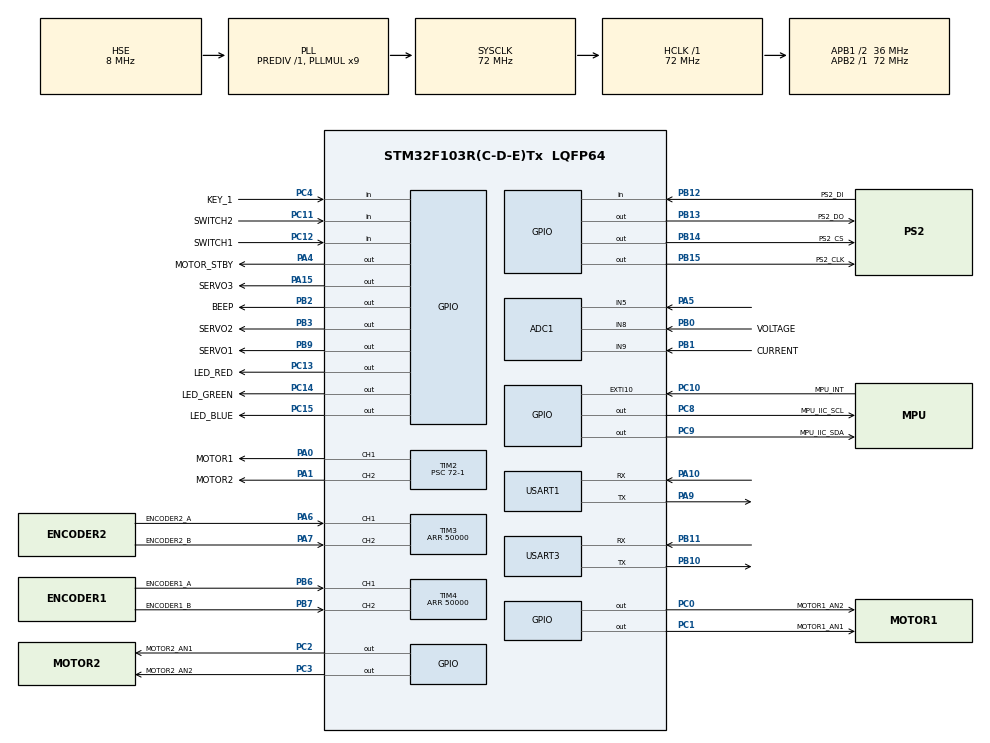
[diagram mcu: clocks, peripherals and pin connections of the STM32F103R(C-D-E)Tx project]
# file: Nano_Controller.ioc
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ADC1.Channel-0\#ChannelRegularConversion=ADC_CHANNEL_8
ADC1.NbrOfConversionFlag=1
ADC1.Rank-0\#ChannelRegularConversion=1
ADC1.SamplingTime-0\#ChannelRegularConversion=ADC_SAMPLETIME_1CYCLE_5
ADC1.master=1
Dma.Request0=USART1_RX
Dma.Request1=USART1_TX
Dma.USART1_RX.0.Direction=DMA_PERIPH_TO_MEMORY
Dma.USART1_RX.0.Instance=DMA1_Channel5
Dma.USART1_RX.0.MemDataAlignment=DMA_MDATAALIGN_BYTE
Dma.USART1_RX.0.MemInc=DMA_MINC_ENABLE
Dma.USART1_RX.0.Mode=DMA_NORMAL
Dma.USART1_RX.0.PeriphDataAlignment=DMA_PDATAALIGN_BYTE
Dma.USART1_RX.0.PeriphInc=DMA_PINC_DISABLE
Dma.USART1_RX.0.Priority=DMA_PRIORITY_LOW
Dma.USART1_TX.1.Direction=DMA_MEMORY_TO_PERIPH
Dma.USART1_TX.1.Instance=DMA1_Channel4
Dma.USART1_TX.1.MemDataAlignment=DMA_MDATAALIGN_BYTE
Dma.USART1_TX.1.MemInc=DMA_MINC_ENABLE
Dma.USART1_TX.1.Mode=DMA_NORMAL
Dma.USART1_TX.1.PeriphDataAlignment=DMA_PDATAALIGN_BYTE
Dma.USART1_TX.1.PeriphInc=DMA_PINC_DISABLE
Dma.USART1_TX.1.Priority=DMA_PRIORITY_LOW
Mcu.Family=STM32F1
Mcu.Name=STM32F103R(C-D-E)Tx
Mcu.Package=LQFP64
NVIC.DMA1_Channel4_IRQn=true\:0\:0\:false\:true\:true\:1\:false\:true
NVIC.DMA1_Channel5_IRQn=true\:0\:0\:false\:true\:true\:2\:false\:true
NVIC.EXTI15_10_IRQn=true\:0\:0\:true\:false\:true\:true\:true
NVIC.PriorityGroup=NVIC_PRIORITYGROUP_4
NVIC.TIM1_UP_IRQn=true\:0\:0\:false\:false\:true\:true\:true
NVIC.TIM3_IRQn=true\:0\:0\:false\:false\:true\:true\:true
NVIC.TIM4_IRQn=true\:0\:0\:false\:false\:true\:true\:true
NVIC.USART1_IRQn=true\:0\:0\:false\:false\:true\:true\:true
PA0-WKUP.GPIO_Label=MOTOR1
PA0-WKUP.Signal=S_TIM2_CH1_ETR
PA1.GPIO_Label=MOTOR2
PA1.Signal=S_TIM2_CH2
PA10.Mode=Asynchronous
PA10.Signal=USART1_RX
PA13.Mode=Serial_Wire
PA13.Signal=SYS_JTMS-SWDIO
PA14.Mode=Serial_Wire
PA14.Signal=SYS_JTCK-SWCLK
PA15.GPIO_Label=SERVO3
PA15.Signal=GPIO_Output
PA4.GPIO_Label=MOTOR_STBY
PA4.Signal=GPIO_Output
PA5.Signal=ADCx_IN5
PA6.GPIO_Label=ENCODER2_A
PA6.GPIO_PuPd=GPIO_PULLUP
PA6.Signal=S_TIM3_CH1
PA7.GPIO_Label=ENCODER2_B
PA7.GPIO_PuPd=GPIO_PULLUP
PA7.Signal=S_TIM3_CH2
PA9.Mode=Asynchronous
PA9.Signal=USART1_TX
PB0.GPIO_Label=VOLTAGE
PB0.Signal=ADCx_IN8
PB1.GPIO_Label=CURRENT
PB1.Signal=ADCx_IN9
PB10.Mode=Asynchronous
PB10.Signal=USART3_TX
PB11.Mode=Asynchronous
PB11.Signal=USART3_RX
PB12.GPIO_Label=PS2_DI
PB12.GPIO_PuPd=GPIO_PULLUP
PB12.Signal=GPIO_Input
PB13.GPIO_Label=PS2_DO
PB13.GPIO_PuPd=GPIO_PULLUP
PB13.Signal=GPIO_Output
PB14.GPIO_Label=PS2_CS
PB14.GPIO_PuPd=GPIO_PULLUP
PB14.Signal=GPIO_Output
PB15.GPIO_Label=PS2_CLK
PB15.GPIO_PuPd=GPIO_PULLUP
PB15.Signal=GPIO_Output
PB2.GPIO_Label=BEEP
PB2.Signal=GPIO_Output
PB3.GPIO_Label=SERVO2
PB3.Signal=GPIO_Output
PB6.GPIO_Label=ENCODER1_A
PB6.GPIO_PuPd=GPIO_PULLUP
PB6.Signal=S_TIM4_CH1
PB7.GPIO_Label=ENCODER1_B
PB7.GPIO_PuPd=GPIO_PULLUP
PB7.Signal=S_TIM4_CH2
PB9.GPIO_Label=SERVO1
PB9.Signal=GPIO_Output
PC0.GPIO_Label=MOTOR1_AN2
PC0.Signal=GPIO_Output
PC1.GPIO_Label=MOTOR1_AN1
PC1.Signal=GPIO_Output
PC10.GPIO_Label=MPU_INT
PC10.Signal=GPXTI10
PC11.GPIO_Label=SWITCH2
PC11.GPIO_PuPd=GPIO_PULLUP
PC11.Signal=GPIO_Input
PC12.GPIO_Label=SWITCH1
PC12.GPIO_PuPd=GPIO_PULLUP
PC12.Signal=GPIO_Input
PC13-TAMPER-RTC.GPIO_Label=LED_RED
PC13-TAMPER-RTC.Signal=GPIO_Output
PC14-OSC32_IN.GPIO_Label=LED_GREEN
PC14-OSC32_IN.Signal=GPIO_Output
PC15-OSC32_OUT.GPIO_Label=LED_BLUE
PC15-OSC32_OUT.Signal=GPIO_Output
PC2.GPIO_Label=MOTOR2_AN1
PC2.Signal=GPIO_Output
PC3.GPIO_Label=MOTOR2_AN2
PC3.Signal=GPIO_Output
PC4.GPIO_Label=KEY_1
PC4.GPIO_PuPd=GPIO_PULLUP
PC4.Signal=GPIO_Input
PC8.GPIO_Label=MPU_IIC_SCL
PC8.Signal=GPIO_Output
PC9.GPIO_Label=MPU_IIC_SDA
PC9.Signal=GPIO_Output
PD0-OSC_IN.Mode=HSE-External-Oscillator
PD0-OSC_IN.Signal=RCC_OSC_IN
PD1-OSC_OUT.Mode=HSE-External-Oscillator
PD1-OSC_OUT.Signal=RCC_OSC_OUT
ProjectManager.HeapSize=0x200
ProjectManager.StackSize=0x400
ProjectManager.TargetToolchain=MDK-ARM V5
RCC.ADCPresc=RCC_ADCPCLK2_DIV6
RCC.AHBFreq_Value=72000000
RCC.APB1CLKDivider=RCC_HCLK_DIV2
RCC.APB1Freq_Value=36000000
RCC.APB1TimFreq_Value=72000000
RCC.APB2Freq_Value=72000000
RCC.APB2TimFreq_Value=72000000
RCC.HCLKFreq_Value=72000000
RCC.PLLMUL=RCC_PLL_MUL9
RCC.PLLSourceVirtual=RCC_PLLSOURCE_HSE
RCC.SYSCLKFreq_VALUE=72000000
RCC.SYSCLKSource=RCC_SYSCLKSOURCE_PLLCLK
RCC.USBFreq_Value=48000000
RCC.USBPrescaler=RCC_USBCLKSOURCE_PLL_DIV1_5
SH.ADCx_IN5.0=ADC1_IN5,IN5
SH.ADCx_IN8.0=ADC1_IN8,IN8
SH.ADCx_IN9.0=ADC1_IN9,IN9
SH.S_TIM2_CH1_ETR.0=TIM2_CH1,PWM Generation1 CH1
SH.S_TIM2_CH2.0=TIM2_CH2,PWM Generation2 CH2
SH.S_TIM3_CH1.0=TIM3_CH1,Encoder_Interface
SH.S_TIM3_CH2.0=TIM3_CH2,Encoder_Interface
SH.S_TIM4_CH1.0=TIM4_CH1,Encoder_Interface
SH.S_TIM4_CH2.0=TIM4_CH2,Encoder_Interface
TIM1.Period=1500-1
TIM1.Prescaler=72-1
TIM2.Channel-PWM\ Generation1\ CH1=TIM_CHANNEL_1
TIM2.Channel-PWM\ Generation2\ CH2=TIM_CHANNEL_2
TIM2.Period=1000-1
TIM2.Prescaler=72-1
TIM3.ClockDivision=TIM_CLOCKDIVISION_DIV4
TIM3.EncoderMode=TIM_ENCODERMODE_TI12
TIM3.IC1Filter=15
TIM3.IC2Filter=15
TIM3.Period=50000
TIM4.ClockDivision=TIM_CLOCKDIVISION_DIV4
TIM4.EncoderMode=TIM_ENCODERMODE_TI12
TIM4.IC1Filter=15
TIM4.IC2Filter=15
TIM4.Period=50000
USART1.VirtualMode=VM_ASYNC
USART3.VirtualMode=VM_ASYNC
VP_TIM1_VS_ClockSourceINT.Mode=Internal
board=custom

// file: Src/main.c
/* USER CODE BEGIN Header */
/**
  ******************************************************************************
  * @file           : main.c
  * @brief          : Main program body
  ******************************************************************************
  ** This notice applies to any and all portions of this file
  * that are not between comment pairs USER CODE BEGIN and
  * USER CODE END. Other portions of this file, whether
  * inserted by the user or by software development tools
  * are owned by their respective copyright owners.
  *
  * COPYRIGHT(c) 2019 STMicroelectronics
  *
  * Redistribution and use in source and binary forms, with or without modification,
  * are permitted provided that the following conditions are met:
  *   1. Redistributions of source code must retain the above copyright notice,
  *      this list of conditions and the following disclaimer.
  *   2. Redistributions in binary form must reproduce the above copyright notice,
  *      this list of conditions and the following disclaimer in the documentation
  *      and/or other materials provided with the distribution.
  *   3. Neither the name of STMicroelectronics nor the names of its contributors
  *      may be used to endorse or promote products derived from this software
  *      without specific prior written permission.
  *
  * THIS SOFTWARE IS PROVIDED BY THE COPYRIGHT HOLDERS AND CONTRIBUTORS "AS IS"
  * AND ANY EXPRESS OR IMPLIED WARRANTIES, INCLUDING, BUT NOT LIMITED TO, THE
  * IMPLIED WARRANTIES OF MERCHANTABILITY AND FITNESS FOR A PARTICULAR PURPOSE ARE
  * DISCLAIMED. IN NO EVENT SHALL THE COPYRIGHT HOLDER OR CONTRIBUTORS BE LIABLE
  * FOR ANY DIRECT, INDIRECT, INCIDENTAL, SPECIAL, EXEMPLARY, OR CONSEQUENTIAL
  * DAMAGES (INCLUDING, BUT NOT LIMITED TO, PROCUREMENT OF SUBSTITUTE GOODS OR
  * SERVICES; LOSS OF USE, DATA, OR PROFITS; OR BUSINESS INTERRUPTION) HOWEVER
  * CAUSED AND ON ANY THEORY OF LIABILITY, WHETHER IN CONTRACT, STRICT LIABILITY,
  * OR TORT (INCLUDING NEGLIGENCE OR OTHERWISE) ARISING IN ANY WAY OUT OF THE USE
  * OF THIS SOFTWARE, EVEN IF ADVISED OF THE POSSIBILITY OF SUCH DAMAGE.
  *
  ******************************************************************************
  */
/* USER CODE END Header */

#include "main.h"

/* USER CODE BEGIN Includes */
#include "mainloop.h"
/* USER CODE END Includes */

ADC_HandleTypeDef hadc1;

TIM_HandleTypeDef htim1;
TIM_HandleTypeDef htim2;
TIM_HandleTypeDef htim3;
TIM_HandleTypeDef htim4;

UART_HandleTypeDef huart1;
UART_HandleTypeDef huart3;
DMA_HandleTypeDef hdma_usart1_rx;
DMA_HandleTypeDef hdma_usart1_tx;

void SystemClock_Config(void);
static void MX_GPIO_Init(void);
static void MX_DMA_Init(void);
static void MX_TIM4_Init(void);
static void MX_ADC1_Init(void);
static void MX_TIM3_Init(void);
static void MX_USART1_UART_Init(void);
static void MX_TIM1_Init(void);
static void MX_TIM2_Init(void);
static void MX_USART3_UART_Init(void);
static void MX_NVIC_Init(void);

int main(void)
{

  /* MCU Configuration--------------------------------------------------------*/

  /* Reset of all peripherals, Initializes the Flash interface and the Systick. */
  HAL_Init();

  /* Configure the system clock */
  SystemClock_Config();

  /* Initialize all configured peripherals */
  MX_GPIO_Init();
  MX_DMA_Init();
  MX_TIM4_Init();
  MX_ADC1_Init();
  MX_TIM3_Init();
  MX_USART1_UART_Init();
  MX_TIM1_Init();
  MX_TIM2_Init();
  MX_USART3_UART_Init();

  /* Initialize interrupts */
  MX_NVIC_Init();

  /* Infinite loop */
  /* USER CODE BEGIN WHILE */

	/*main loop*/
  while (1){
		vMainLoop();
    /* USER CODE END WHILE */

  }
}

void SystemClock_Config(void)
{
  RCC_OscInitTypeDef RCC_OscInitStruct = {0};
  RCC_ClkInitTypeDef RCC_ClkInitStruct = {0};
  RCC_PeriphCLKInitTypeDef PeriphClkInit = {0};

  /** Initializes the CPU, AHB and APB busses clocks
  */
  RCC_OscInitStruct.OscillatorType = RCC_OSCILLATORTYPE_HSE;
  RCC_OscInitStruct.HSEState = RCC_HSE_ON;
  RCC_OscInitStruct.HSEPredivValue = RCC_HSE_PREDIV_DIV1;
  RCC_OscInitStruct.HSIState = RCC_HSI_ON;
  RCC_OscInitStruct.PLL.PLLState = RCC_PLL_ON;
  RCC_OscInitStruct.PLL.PLLSource = RCC_PLLSOURCE_HSE;
  RCC_OscInitStruct.PLL.PLLMUL = RCC_PLL_MUL9;
  if (HAL_RCC_OscConfig(&RCC_OscInitStruct) != HAL_OK)
  {
    Error_Handler();
  }
  /** Initializes the CPU, AHB and APB busses clocks
  */
  RCC_ClkInitStruct.ClockType = RCC_CLOCKTYPE_HCLK|RCC_CLOCKTYPE_SYSCLK
                              |RCC_CLOCKTYPE_PCLK1|RCC_CLOCKTYPE_PCLK2;
  RCC_ClkInitStruct.SYSCLKSource = RCC_SYSCLKSOURCE_PLLCLK;
  RCC_ClkInitStruct.AHBCLKDivider = RCC_SYSCLK_DIV1;
  RCC_ClkInitStruct.APB1CLKDivider = RCC_HCLK_DIV2;
  RCC_ClkInitStruct.APB2CLKDivider = RCC_HCLK_DIV1;

  if (HAL_RCC_ClockConfig(&RCC_ClkInitStruct, FLASH_LATENCY_2) != HAL_OK)
  {
    Error_Handler();
  }
  PeriphClkInit.PeriphClockSelection = RCC_PERIPHCLK_ADC;
  PeriphClkInit.AdcClockSelection = RCC_ADCPCLK2_DIV6;
  if (HAL_RCCEx_PeriphCLKConfig(&PeriphClkInit) != HAL_OK)
  {
    Error_Handler();
  }
}

/**
  * @brief NVIC Configuration.
  * @retval None
  */
static void MX_NVIC_Init(void)
{
  /* DMA1_Channel4_IRQn interrupt configuration */
  HAL_NVIC_SetPriority(DMA1_Channel4_IRQn, 0, 0);
  HAL_NVIC_EnableIRQ(DMA1_Channel4_IRQn);
  /* DMA1_Channel5_IRQn interrupt configuration */
  HAL_NVIC_SetPriority(DMA1_Channel5_IRQn, 0, 0);
  HAL_NVIC_EnableIRQ(DMA1_Channel5_IRQn);
}

static void MX_ADC1_Init(void)
{

  ADC_ChannelConfTypeDef sConfig = {0};

  /** Common config
  */
  hadc1.Instance = ADC1;
  hadc1.Init.ScanConvMode = ADC_SCAN_DISABLE;
  hadc1.Init.ContinuousConvMode = DISABLE;
  hadc1.Init.DiscontinuousConvMode = DISABLE;
  hadc1.Init.ExternalTrigConv = ADC_SOFTWARE_START;
  hadc1.Init.DataAlign = ADC_DATAALIGN_RIGHT;
  hadc1.Init.NbrOfConversion = 1;
  if (HAL_ADC_Init(&hadc1) != HAL_OK)
  {
    Error_Handler();
  }
  /** Configure Regular Channel
  */
  sConfig.Channel = ADC_CHANNEL_8;
  sConfig.Rank = ADC_REGULAR_RANK_1;
  sConfig.SamplingTime = ADC_SAMPLETIME_1CYCLE_5;
  if (HAL_ADC_ConfigChannel(&hadc1, &sConfig) != HAL_OK)
  {
    Error_Handler();
  }

}

static void MX_TIM1_Init(void)
{

  TIM_ClockConfigTypeDef sClockSourceConfig = {0};
  TIM_MasterConfigTypeDef sMasterConfig = {0};

  htim1.Instance = TIM1;
  htim1.Init.Prescaler = 72-1;
  htim1.Init.CounterMode = TIM_COUNTERMODE_UP;
  htim1.Init.Period = 1500-1;
  htim1.Init.ClockDivision = TIM_CLOCKDIVISION_DIV1;
  htim1.Init.RepetitionCounter = 0;
  htim1.Init.AutoReloadPreload = TIM_AUTORELOAD_PRELOAD_DISABLE;
  if (HAL_TIM_Base_Init(&htim1) != HAL_OK)
  {
    Error_Handler();
  }
  sClockSourceConfig.ClockSource = TIM_CLOCKSOURCE_INTERNAL;
  if (HAL_TIM_ConfigClockSource(&htim1, &sClockSourceConfig) != HAL_OK)
  {
    Error_Handler();
  }
  sMasterConfig.MasterOutputTrigger = TIM_TRGO_RESET;
  sMasterConfig.MasterSlaveMode = TIM_MASTERSLAVEMODE_DISABLE;
  if (HAL_TIMEx_MasterConfigSynchronization(&htim1, &sMasterConfig) != HAL_OK)
  {
    Error_Handler();
  }

}

static void MX_TIM2_Init(void)
{

  TIM_MasterConfigTypeDef sMasterConfig = {0};
  TIM_OC_InitTypeDef sConfigOC = {0};

  htim2.Instance = TIM2;
  htim2.Init.Prescaler = 72-1;
  htim2.Init.CounterMode = TIM_COUNTERMODE_UP;
  htim2.Init.Period = 1000-1;
  htim2.Init.ClockDivision = TIM_CLOCKDIVISION_DIV1;
  htim2.Init.AutoReloadPreload = TIM_AUTORELOAD_PRELOAD_DISABLE;
  if (HAL_TIM_PWM_Init(&htim2) != HAL_OK)
  {
    Error_Handler();
  }
  sMasterConfig.MasterOutputTrigger = TIM_TRGO_RESET;
  sMasterConfig.MasterSlaveMode = TIM_MASTERSLAVEMODE_DISABLE;
  if (HAL_TIMEx_MasterConfigSynchronization(&htim2, &sMasterConfig) != HAL_OK)
  {
    Error_Handler();
  }
  sConfigOC.OCMode = TIM_OCMODE_PWM1;
  sConfigOC.Pulse = 0;
  sConfigOC.OCPolarity = TIM_OCPOLARITY_HIGH;
  sConfigOC.OCFastMode = TIM_OCFAST_DISABLE;
  if (HAL_TIM_PWM_ConfigChannel(&htim2, &sConfigOC, TIM_CHANNEL_1) != HAL_OK)
  {
    Error_Handler();
  }
  if (HAL_TIM_PWM_ConfigChannel(&htim2, &sConfigOC, TIM_CHANNEL_2) != HAL_OK)
  {
    Error_Handler();
  }
  HAL_TIM_MspPostInit(&htim2);

}

static void MX_TIM3_Init(void)
{

  TIM_Encoder_InitTypeDef sConfig = {0};
  TIM_MasterConfigTypeDef sMasterConfig = {0};

  htim3.Instance = TIM3;
  htim3.Init.Prescaler = 0;
  htim3.Init.CounterMode = TIM_COUNTERMODE_UP;
  htim3.Init.Period = 50000;
  htim3.Init.ClockDivision = TIM_CLOCKDIVISION_DIV4;
  htim3.Init.AutoReloadPreload = TIM_AUTORELOAD_PRELOAD_DISABLE;
  sConfig.EncoderMode = TIM_ENCODERMODE_TI12;
  sConfig.IC1Polarity = TIM_ICPOLARITY_RISING;
  sConfig.IC1Selection = TIM_ICSELECTION_DIRECTTI;
  sConfig.IC1Prescaler = TIM_ICPSC_DIV1;
  sConfig.IC1Filter = 15;
  sConfig.IC2Polarity = TIM_ICPOLARITY_RISING;
  sConfig.IC2Selection = TIM_ICSELECTION_DIRECTTI;
  sConfig.IC2Prescaler = TIM_ICPSC_DIV1;
  sConfig.IC2Filter = 15;
  if (HAL_TIM_Encoder_Init(&htim3, &sConfig) != HAL_OK)
  {
    Error_Handler();
  }
  sMasterConfig.MasterOutputTrigger = TIM_TRGO_RESET;
  sMasterConfig.MasterSlaveMode = TIM_MASTERSLAVEMODE_DISABLE;
  if (HAL_TIMEx_MasterConfigSynchronization(&htim3, &sMasterConfig) != HAL_OK)
  {
    Error_Handler();
  }

}

static void MX_TIM4_Init(void)
{

  TIM_Encoder_InitTypeDef sConfig = {0};
  TIM_MasterConfigTypeDef sMasterConfig = {0};

  htim4.Instance = TIM4;
  htim4.Init.Prescaler = 0;
  htim4.Init.CounterMode = TIM_COUNTERMODE_UP;
  htim4.Init.Period = 50000;
  htim4.Init.ClockDivision = TIM_CLOCKDIVISION_DIV4;
  htim4.Init.AutoReloadPreload = TIM_AUTORELOAD_PRELOAD_DISABLE;
  sConfig.EncoderMode = TIM_ENCODERMODE_TI12;
  sConfig.IC1Polarity = TIM_ICPOLARITY_RISING;
  sConfig.IC1Selection = TIM_ICSELECTION_DIRECTTI;
  sConfig.IC1Prescaler = TIM_ICPSC_DIV1;
  sConfig.IC1Filter = 15;
  sConfig.IC2Polarity = TIM_ICPOLARITY_RISING;
  sConfig.IC2Selection = TIM_ICSELECTION_DIRECTTI;
  sConfig.IC2Prescaler = TIM_ICPSC_DIV1;
  sConfig.IC2Filter = 15;
  if (HAL_TIM_Encoder_Init(&htim4, &sConfig) != HAL_OK)
  {
    Error_Handler();
  }
  sMasterConfig.MasterOutputTrigger = TIM_TRGO_RESET;
  sMasterConfig.MasterSlaveMode = TIM_MASTERSLAVEMODE_DISABLE;
  if (HAL_TIMEx_MasterConfigSynchronization(&htim4, &sMasterConfig) != HAL_OK)
  {
    Error_Handler();
  }

}

static void MX_USART1_UART_Init(void)
{

  huart1.Instance = USART1;
  huart1.Init.BaudRate = 115200;
  huart1.Init.WordLength = UART_WORDLENGTH_8B;
  huart1.Init.StopBits = UART_STOPBITS_1;
  huart1.Init.Parity = UART_PARITY_NONE;
  huart1.Init.Mode = UART_MODE_TX_RX;
  huart1.Init.HwFlowCtl = UART_HWCONTROL_NONE;
  huart1.Init.OverSampling = UART_OVERSAMPLING_16;
  if (HAL_UART_Init(&huart1) != HAL_OK)
  {
    Error_Handler();
  }

}

static void MX_USART3_UART_Init(void)
{

  huart3.Instance = USART3;
  huart3.Init.BaudRate = 115200;
  huart3.Init.WordLength = UART_WORDLENGTH_8B;
  huart3.Init.StopBits = UART_STOPBITS_1;
  huart3.Init.Parity = UART_PARITY_NONE;
  huart3.Init.Mode = UART_MODE_TX_RX;
  huart3.Init.HwFlowCtl = UART_HWCONTROL_NONE;
  huart3.Init.OverSampling = UART_OVERSAMPLING_16;
  if (HAL_UART_Init(&huart3) != HAL_OK)
  {
    Error_Handler();
  }

}

static void MX_DMA_Init(void)
{
  /* DMA controller clock enable */
  __HAL_RCC_DMA1_CLK_ENABLE();

}

static void MX_GPIO_Init(void)
{
  GPIO_InitTypeDef GPIO_InitStruct = {0};

  /* GPIO Ports Clock Enable */
  __HAL_RCC_GPIOC_CLK_ENABLE();
  __HAL_RCC_GPIOD_CLK_ENABLE();
  __HAL_RCC_GPIOA_CLK_ENABLE();
  __HAL_RCC_GPIOB_CLK_ENABLE();

  /*Configure GPIO pin Output Level */
  HAL_GPIO_WritePin(GPIOC, LED_RED_Pin|LED_GREEN_Pin|LED_BLUE_Pin|MOTOR1_AN2_Pin
                          |MOTOR1_AN1_Pin|MOTOR2_AN1_Pin|MOTOR2_AN2_Pin|MPU_IIC_SCL_Pin
                          |MPU_IIC_SDA_Pin, GPIO_PIN_RESET);

  /*Configure GPIO pin Output Level */
  HAL_GPIO_WritePin(GPIOA, MOTOR_STBY_Pin|SERVO3_Pin, GPIO_PIN_RESET);

  /*Configure GPIO pin Output Level */
  HAL_GPIO_WritePin(GPIOB, BEEP_Pin|PS2_DO_Pin|PS2_CS_Pin|PS2_CLK_Pin
                          |SERVO2_Pin|SERVO1_Pin, GPIO_PIN_RESET);

  /*Configure GPIO pins : LED_RED_Pin LED_GREEN_Pin LED_BLUE_Pin MOTOR1_AN2_Pin
                           MOTOR1_AN1_Pin MOTOR2_AN1_Pin MOTOR2_AN2_Pin MPU_IIC_SCL_Pin
                           MPU_IIC_SDA_Pin */
  GPIO_InitStruct.Pin = LED_RED_Pin|LED_GREEN_Pin|LED_BLUE_Pin|MOTOR1_AN2_Pin
                          |MOTOR1_AN1_Pin|MOTOR2_AN1_Pin|MOTOR2_AN2_Pin|MPU_IIC_SCL_Pin
                          |MPU_IIC_SDA_Pin;
  GPIO_InitStruct.Mode = GPIO_MODE_OUTPUT_PP;
  GPIO_InitStruct.Pull = GPIO_NOPULL;
  GPIO_InitStruct.Speed = GPIO_SPEED_FREQ_LOW;
  HAL_GPIO_Init(GPIOC, &GPIO_InitStruct);

  /*Configure GPIO pins : MOTOR_STBY_Pin SERVO3_Pin */
  GPIO_InitStruct.Pin = MOTOR_STBY_Pin|SERVO3_Pin;
  GPIO_InitStruct.Mode = GPIO_MODE_OUTPUT_PP;
  GPIO_InitStruct.Pull = GPIO_NOPULL;
  GPIO_InitStruct.Speed = GPIO_SPEED_FREQ_LOW;
  HAL_GPIO_Init(GPIOA, &GPIO_InitStruct);

  /*Configure GPIO pins : KEY_1_Pin SWITCH2_Pin SWITCH1_Pin */
  GPIO_InitStruct.Pin = KEY_1_Pin|SWITCH2_Pin|SWITCH1_Pin;
  GPIO_InitStruct.Mode = GPIO_MODE_INPUT;
  GPIO_InitStruct.Pull = GPIO_PULLUP;
  HAL_GPIO_Init(GPIOC, &GPIO_InitStruct);

  /*Configure GPIO pins : BEEP_Pin SERVO2_Pin SERVO1_Pin */
  GPIO_InitStruct.Pin = BEEP_Pin|SERVO2_Pin|SERVO1_Pin;
  GPIO_InitStruct.Mode = GPIO_MODE_OUTPUT_PP;
  GPIO_InitStruct.Pull = GPIO_NOPULL;
  GPIO_InitStruct.Speed = GPIO_SPEED_FREQ_LOW;
  HAL_GPIO_Init(GPIOB, &GPIO_InitStruct);

  /*Configure GPIO pin : PS2_DI_Pin */
  GPIO_InitStruct.Pin = PS2_DI_Pin;
  GPIO_InitStruct.Mode = GPIO_MODE_INPUT;
  GPIO_InitStruct.Pull = GPIO_PULLUP;
  HAL_GPIO_Init(PS2_DI_GPIO_Port, &GPIO_InitStruct);

  /*Configure GPIO pins : PS2_DO_Pin PS2_CS_Pin PS2_CLK_Pin */
  GPIO_InitStruct.Pin = PS2_DO_Pin|PS2_CS_Pin|PS2_CLK_Pin;
  GPIO_InitStruct.Mode = GPIO_MODE_OUTPUT_PP;
  GPIO_InitStruct.Pull = GPIO_PULLUP;
  GPIO_InitStruct.Speed = GPIO_SPEED_FREQ_LOW;
  HAL_GPIO_Init(GPIOB, &GPIO_InitStruct);

  /*Configure GPIO pin : MPU_INT_Pin */
  GPIO_InitStruct.Pin = MPU_INT_Pin;
  GPIO_InitStruct.Mode = GPIO_MODE_IT_RISING;
  GPIO_InitStruct.Pull = GPIO_NOPULL;
  HAL_GPIO_Init(MPU_INT_GPIO_Port, &GPIO_InitStruct);

  /* EXTI interrupt init*/
  HAL_NVIC_SetPriority(EXTI15_10_IRQn, 0, 0);
  HAL_NVIC_EnableIRQ(EXTI15_10_IRQn);

}

void Error_Handler(void)
{
}

/************************ (C) COPYRIGHT STMicroelectronics *****END OF FILE****/
